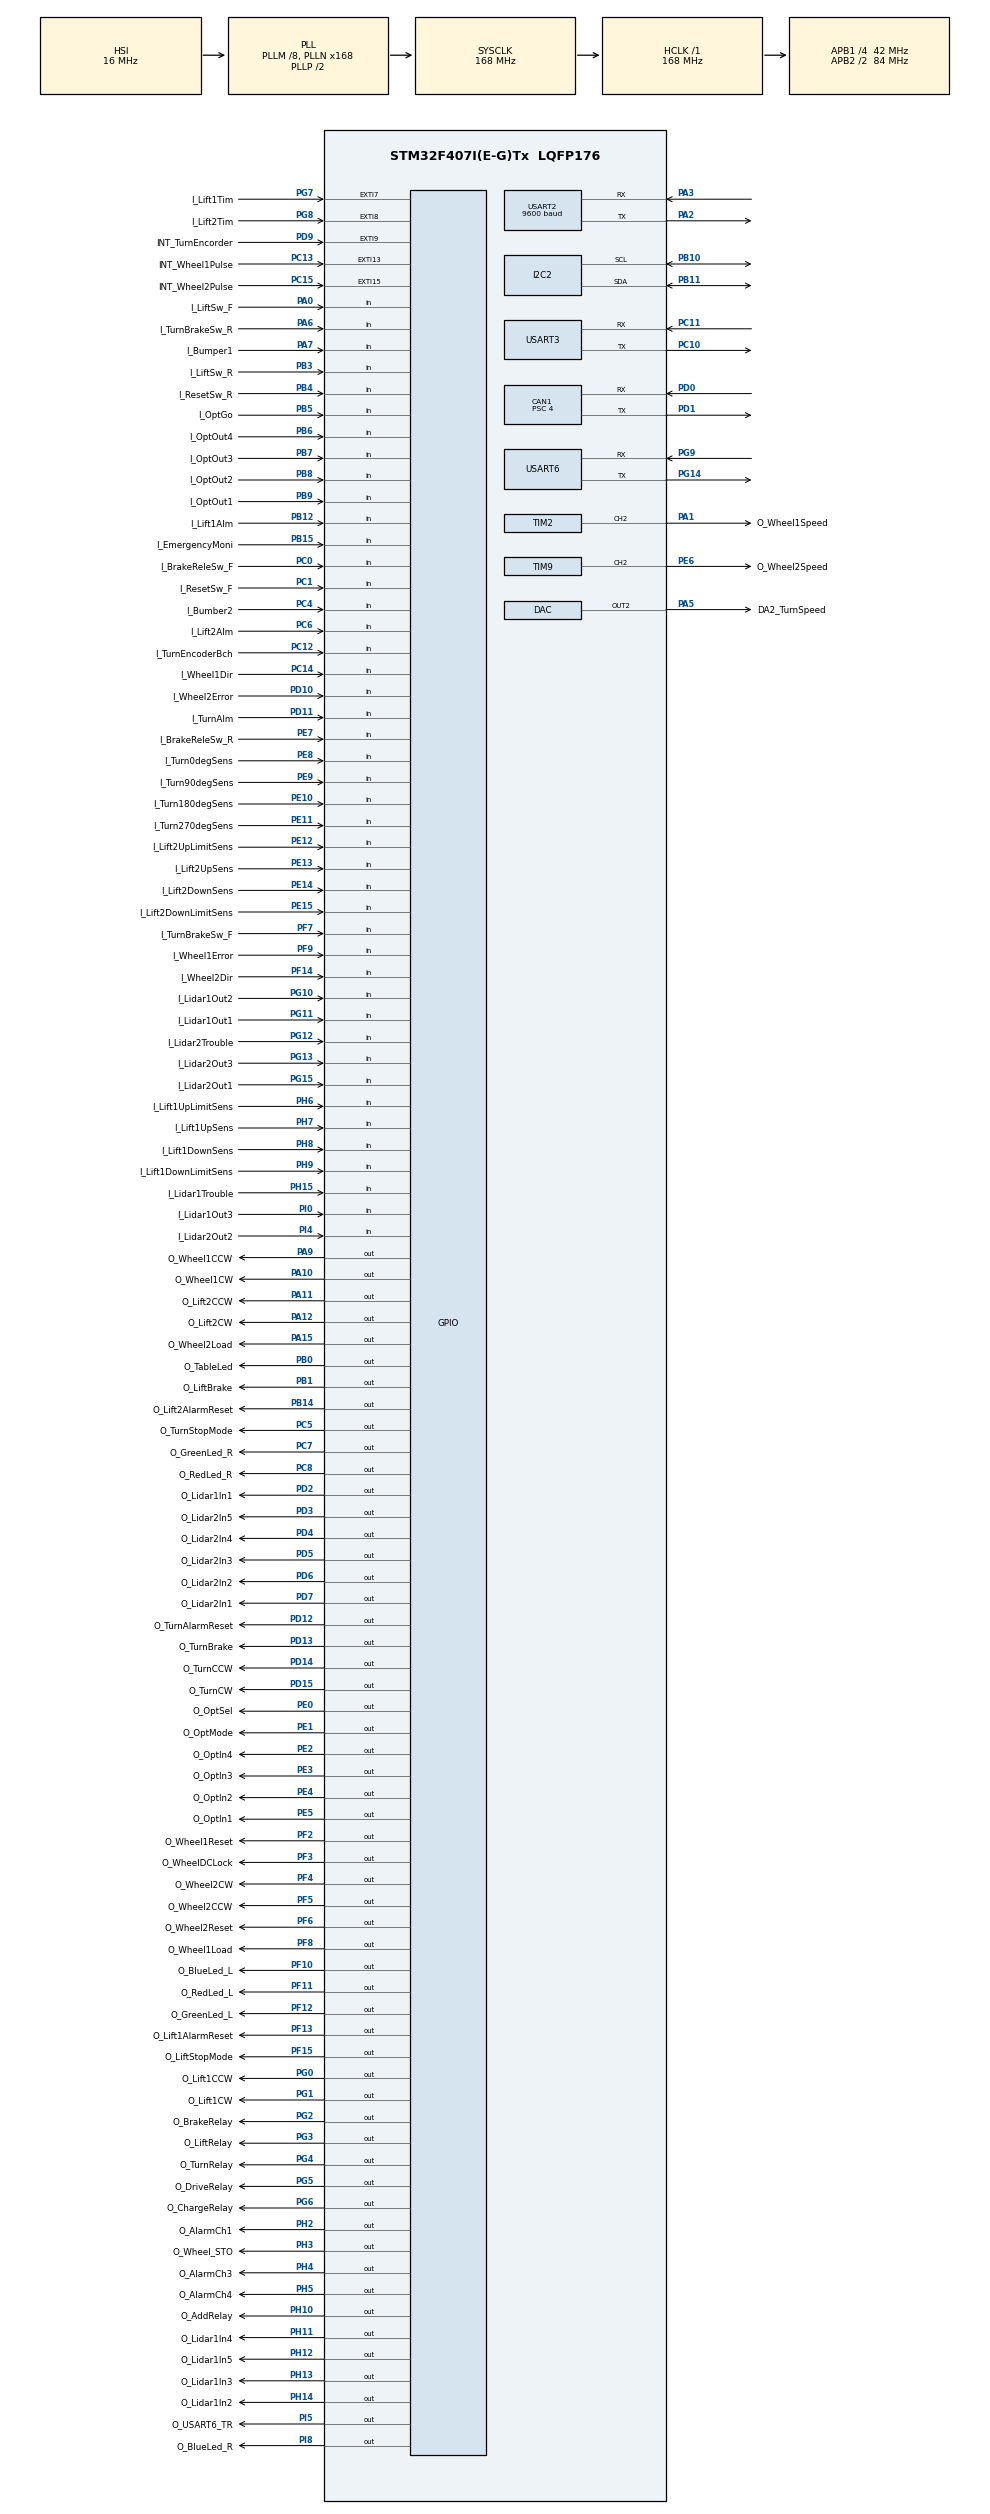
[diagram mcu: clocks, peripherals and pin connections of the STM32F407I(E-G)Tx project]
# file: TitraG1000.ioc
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CAN1.BS1=CAN_BS1_15TQ
CAN1.BS2=CAN_BS2_5TQ
CAN1.CalculateTimeQuantum=95.23809523809524
CAN1.Prescaler=4
Dma.Request0=USART2_RX
Dma.Request1=USART2_TX
Dma.Request2=USART3_TX
Dma.Request3=USART3_RX
Dma.Request4=USART6_TX
Dma.USART2_RX.0.Direction=DMA_PERIPH_TO_MEMORY
Dma.USART2_RX.0.FIFOMode=DMA_FIFOMODE_DISABLE
Dma.USART2_RX.0.Instance=DMA1_Stream5
Dma.USART2_RX.0.MemDataAlignment=DMA_MDATAALIGN_BYTE
Dma.USART2_RX.0.MemInc=DMA_MINC_ENABLE
Dma.USART2_RX.0.Mode=DMA_CIRCULAR
Dma.USART2_RX.0.PeriphDataAlignment=DMA_PDATAALIGN_BYTE
Dma.USART2_RX.0.PeriphInc=DMA_PINC_DISABLE
Dma.USART2_RX.0.Priority=DMA_PRIORITY_MEDIUM
Dma.USART2_TX.1.Direction=DMA_MEMORY_TO_PERIPH
Dma.USART2_TX.1.FIFOMode=DMA_FIFOMODE_DISABLE
Dma.USART2_TX.1.Instance=DMA1_Stream6
Dma.USART2_TX.1.MemDataAlignment=DMA_MDATAALIGN_BYTE
Dma.USART2_TX.1.MemInc=DMA_MINC_ENABLE
Dma.USART2_TX.1.Mode=DMA_NORMAL
Dma.USART2_TX.1.PeriphDataAlignment=DMA_PDATAALIGN_BYTE
Dma.USART2_TX.1.PeriphInc=DMA_PINC_DISABLE
Dma.USART2_TX.1.Priority=DMA_PRIORITY_MEDIUM
Dma.USART3_RX.3.Direction=DMA_PERIPH_TO_MEMORY
Dma.USART3_RX.3.FIFOMode=DMA_FIFOMODE_DISABLE
Dma.USART3_RX.3.Instance=DMA1_Stream1
Dma.USART3_RX.3.MemDataAlignment=DMA_MDATAALIGN_BYTE
Dma.USART3_RX.3.MemInc=DMA_MINC_ENABLE
Dma.USART3_RX.3.Mode=DMA_CIRCULAR
Dma.USART3_RX.3.PeriphDataAlignment=DMA_PDATAALIGN_BYTE
Dma.USART3_RX.3.PeriphInc=DMA_PINC_DISABLE
Dma.USART3_RX.3.Priority=DMA_PRIORITY_HIGH
Dma.USART3_TX.2.Direction=DMA_MEMORY_TO_PERIPH
Dma.USART3_TX.2.FIFOMode=DMA_FIFOMODE_DISABLE
Dma.USART3_TX.2.Instance=DMA1_Stream3
Dma.USART3_TX.2.MemDataAlignment=DMA_MDATAALIGN_BYTE
Dma.USART3_TX.2.MemInc=DMA_MINC_ENABLE
Dma.USART3_TX.2.Mode=DMA_NORMAL
Dma.USART3_TX.2.PeriphDataAlignment=DMA_PDATAALIGN_BYTE
Dma.USART3_TX.2.PeriphInc=DMA_PINC_DISABLE
Dma.USART3_TX.2.Priority=DMA_PRIORITY_HIGH
Dma.USART6_TX.4.Direction=DMA_MEMORY_TO_PERIPH
Dma.USART6_TX.4.FIFOMode=DMA_FIFOMODE_DISABLE
Dma.USART6_TX.4.Instance=DMA2_Stream6
Dma.USART6_TX.4.MemDataAlignment=DMA_MDATAALIGN_BYTE
Dma.USART6_TX.4.MemInc=DMA_MINC_ENABLE
Dma.USART6_TX.4.Mode=DMA_NORMAL
Dma.USART6_TX.4.PeriphDataAlignment=DMA_PDATAALIGN_BYTE
Dma.USART6_TX.4.PeriphInc=DMA_PINC_DISABLE
Dma.USART6_TX.4.Priority=DMA_PRIORITY_LOW
Mcu.Family=STM32F4
Mcu.Name=STM32F407I(E-G)Tx
Mcu.Package=LQFP176
NVIC.CAN1_RX0_IRQn=true\:0\:0\:false\:false\:true\:true\:true
NVIC.DMA1_Stream1_IRQn=true\:0\:0\:false\:false\:true\:false\:true
NVIC.DMA1_Stream3_IRQn=true\:0\:0\:false\:false\:true\:false\:true
NVIC.DMA1_Stream5_IRQn=true\:0\:0\:false\:false\:true\:false\:true
NVIC.DMA1_Stream6_IRQn=true\:0\:0\:false\:false\:true\:false\:true
NVIC.DMA2_Stream6_IRQn=true\:0\:0\:false\:false\:true\:false\:true
NVIC.EXTI15_10_IRQn=true\:0\:0\:false\:false\:true\:true\:true
NVIC.EXTI9_5_IRQn=true\:0\:0\:false\:false\:true\:true\:true
NVIC.PriorityGroup=NVIC_PRIORITYGROUP_4
NVIC.TIM4_IRQn=true\:0\:0\:false\:false\:true\:true\:true
NVIC.USART2_IRQn=true\:0\:0\:false\:false\:true\:true\:true
NVIC.USART3_IRQn=true\:0\:0\:false\:false\:true\:true\:true
NVIC.USART6_IRQn=true\:0\:0\:false\:false\:true\:true\:true
PA0-WKUP.GPIO_Label=I_LiftSw_F
PA0-WKUP.Signal=GPIO_Input
PA1.GPIO_Label=O_Wheel1Speed
PA1.Signal=S_TIM2_CH2
PA10.GPIO_Label=O_Wheel1CW
PA10.Signal=GPIO_Output
PA11.GPIO_Label=O_Lift2CCW
PA11.GPIO_PuPd=GPIO_PULLUP
PA11.Signal=GPIO_Output
PA12.GPIO_Label=O_Lift2CW
PA12.GPIO_PuPd=GPIO_PULLUP
PA12.Signal=GPIO_Output
PA15.GPIO_Label=O_Wheel2Load
PA15.Signal=GPIO_Output
PA2.Mode=IrDA
PA2.Signal=USART2_TX
PA3.Mode=IrDA
PA3.Signal=USART2_RX
PA5.GPIO_Label=DA2_TurnSpeed
PA5.Signal=COMP_DAC2_group
PA6.GPIO_Label=I_TurnBrakeSw_R
PA6.Signal=GPIO_Input
PA7.GPIO_Label=I_Bumper1
PA7.Signal=GPIO_Input
PA9.GPIO_Label=O_Wheel1CCW
PA9.Signal=GPIO_Output
PB0.GPIO_Label=O_TableLed
PB0.Signal=GPIO_Output
PB1.GPIO_Label=O_LiftBrake
PB1.GPIO_PuPd=GPIO_PULLUP
PB1.Signal=GPIO_Output
PB10.Mode=I2C
PB10.Signal=I2C2_SCL
PB11.Mode=I2C
PB11.Signal=I2C2_SDA
PB12.GPIO_Label=I_Lift1Alm
PB12.Signal=GPIO_Input
PB14.GPIO_Label=O_Lift2AlarmReset
PB14.GPIO_PuPd=GPIO_PULLUP
PB14.Signal=GPIO_Output
PB15.GPIO_Label=I_EmergencyMoni
PB15.Signal=GPIO_Input
PB3.GPIO_Label=I_LiftSw_R
PB3.Signal=GPIO_Input
PB4.GPIO_Label=I_ResetSw_R
PB4.Signal=GPIO_Input
PB5.GPIO_Label=I_OptGo
PB5.Signal=GPIO_Input
PB6.GPIO_Label=I_OptOut4
PB6.Signal=GPIO_Input
PB7.GPIO_Label=I_OptOut3
PB7.Signal=GPIO_Input
PB8.GPIO_Label=I_OptOut2
PB8.Signal=GPIO_Input
PB9.GPIO_Label=I_OptOut1
PB9.Signal=GPIO_Input
PC0.GPIO_Label=I_BrakeReleSw_F
PC0.Signal=GPIO_Input
PC1.GPIO_Label=I_ResetSw_F
PC1.Signal=GPIO_Input
PC10.Mode=Asynchronous
PC10.Signal=USART3_TX
PC11.Mode=Asynchronous
PC11.Signal=USART3_RX
PC12.GPIO_Label=I_TurnEncoderBch
PC12.Signal=GPIO_Input
PC13-ANTI_TAMP.GPIO_Label=INT_Wheel1Pulse
PC13-ANTI_TAMP.Signal=GPXTI13
PC14-OSC32_IN.GPIO_Label=I_Wheel1Dir
PC14-OSC32_IN.Signal=GPIO_Input
PC15-OSC32_OUT.GPIO_Label=INT_Wheel2Pulse
PC15-OSC32_OUT.Signal=GPXTI15
PC4.GPIO_Label=I_Bumber2
PC4.Signal=GPIO_Input
PC5.GPIO_Label=O_TurnStopMode
PC5.GPIO_PuPd=GPIO_PULLUP
PC5.Signal=GPIO_Output
PC6.GPIO_Label=I_Lift2Alm
PC6.Signal=GPIO_Input
PC7.GPIO_Label=O_GreenLed_R
PC7.Signal=GPIO_Output
PC8.GPIO_Label=O_RedLed_R
PC8.Signal=GPIO_Output
PD0.Mode=Master
PD0.Signal=CAN1_RX
PD1.Mode=Master
PD1.Signal=CAN1_TX
PD10.GPIO_Label=I_Wheel2Error
PD10.Signal=GPIO_Input
PD11.GPIO_Label=I_TurnAlm
PD11.Signal=GPIO_Input
PD12.GPIO_Label=O_TurnAlarmReset
PD12.GPIO_PuPd=GPIO_PULLUP
PD12.Signal=GPIO_Output
PD13.GPIO_Label=O_TurnBrake
PD13.GPIO_PuPd=GPIO_PULLUP
PD13.Signal=GPIO_Output
PD14.GPIO_Label=O_TurnCCW
PD14.GPIO_PuPd=GPIO_PULLUP
PD14.Signal=GPIO_Output
PD15.GPIO_Label=O_TurnCW
PD15.GPIO_PuPd=GPIO_PULLUP
PD15.Signal=GPIO_Output
PD2.GPIO_Label=O_Lidar1In1
PD2.Signal=GPIO_Output
PD3.GPIO_Label=O_Lidar2In5
PD3.Signal=GPIO_Output
PD4.GPIO_Label=O_Lidar2In4
PD4.Signal=GPIO_Output
PD5.GPIO_Label=O_Lidar2In3
PD5.Signal=GPIO_Output
PD6.GPIO_Label=O_Lidar2In2
PD6.Signal=GPIO_Output
PD7.GPIO_Label=O_Lidar2In1
PD7.Signal=GPIO_Output
PD9.GPIO_Label=INT_TurnEncorder
PD9.Signal=GPXTI9
PE0.GPIO_Label=O_OptSel
PE0.Signal=GPIO_Output
PE1.GPIO_Label=O_OptMode
PE1.Signal=GPIO_Output
PE10.GPIO_Label=I_Turn180degSens
PE10.GPIO_PuPd=GPIO_PULLUP
PE10.Signal=GPIO_Input
PE11.GPIO_Label=I_Turn270degSens
PE11.GPIO_PuPd=GPIO_PULLUP
PE11.Signal=GPIO_Input
PE12.GPIO_Label=I_Lift2UpLimitSens
PE12.GPIO_PuPd=GPIO_PULLUP
PE12.Signal=GPIO_Input
PE13.GPIO_Label=I_Lift2UpSens
PE13.GPIO_PuPd=GPIO_PULLUP
PE13.Signal=GPIO_Input
PE14.GPIO_Label=I_Lift2DownSens
PE14.GPIO_PuPd=GPIO_PULLUP
PE14.Signal=GPIO_Input
PE15.GPIO_Label=I_Lift2DownLimitSens
PE15.GPIO_PuPd=GPIO_PULLUP
PE15.Signal=GPIO_Input
PE2.GPIO_Label=O_OptIn4
PE2.Signal=GPIO_Output
PE3.GPIO_Label=O_OptIn3
PE3.Signal=GPIO_Output
PE4.GPIO_Label=O_OptIn2
PE4.Signal=GPIO_Output
PE5.GPIO_Label=O_OptIn1
PE5.Signal=GPIO_Output
PE6.GPIO_Label=O_Wheel2Speed
PE6.Signal=S_TIM9_CH2
PE7.GPIO_Label=I_BrakeReleSw_R
PE7.Signal=GPIO_Input
PE8.GPIO_Label=I_Turn0degSens
PE8.GPIO_PuPd=GPIO_PULLUP
PE8.Signal=GPIO_Input
PE9.GPIO_Label=I_Turn90degSens
PE9.GPIO_PuPd=GPIO_PULLUP
PE9.Signal=GPIO_Input
PF10.GPIO_Label=O_BlueLed_L
PF10.Signal=GPIO_Output
PF11.GPIO_Label=O_RedLed_L
PF11.Signal=GPIO_Output
PF12.GPIO_Label=O_GreenLed_L
PF12.Signal=GPIO_Output
PF13.GPIO_Label=O_Lift1AlarmReset
PF13.GPIO_PuPd=GPIO_PULLUP
PF13.Signal=GPIO_Output
PF14.GPIO_Label=I_Wheel2Dir
PF14.Signal=GPIO_Input
PF15.GPIO_Label=O_LiftStopMode
PF15.GPIO_PuPd=GPIO_PULLUP
PF15.Signal=GPIO_Output
PF2.GPIO_Label=O_Wheel1Reset
PF2.Signal=GPIO_Output
PF3.GPIO_Label=O_WheelDCLock
PF3.Signal=GPIO_Output
PF4.GPIO_Label=O_Wheel2CW
PF4.Signal=GPIO_Output
PF5.GPIO_Label=O_Wheel2CCW
PF5.Signal=GPIO_Output
PF6.GPIO_Label=O_Wheel2Reset
PF6.Signal=GPIO_Output
PF7.GPIO_Label=I_TurnBrakeSw_F
PF7.Signal=GPIO_Input
PF8.GPIO_Label=O_Wheel1Load
PF8.Signal=GPIO_Output
PF9.GPIO_Label=I_Wheel1Error
PF9.Signal=GPIO_Input
PG0.GPIO_Label=O_Lift1CCW
PG0.GPIO_PuPd=GPIO_PULLUP
PG0.Signal=GPIO_Output
PG1.GPIO_Label=O_Lift1CW
PG1.GPIO_PuPd=GPIO_PULLUP
PG1.Signal=GPIO_Output
PG10.GPIO_Label=I_Lidar1Out2
PG10.Signal=GPIO_Input
PG11.GPIO_Label=I_Lidar1Out1
PG11.Signal=GPIO_Input
PG12.GPIO_Label=I_Lidar2Trouble
PG12.Signal=GPIO_Input
PG13.GPIO_Label=I_Lidar2Out3
PG13.Signal=GPIO_Input
PG14.Mode=Asynchronous
PG14.Signal=USART6_TX
PG15.GPIO_Label=I_Lidar2Out1
PG15.Signal=GPIO_Input
PG2.GPIO_Label=O_BrakeRelay
PG2.Signal=GPIO_Output
PG3.GPIO_Label=O_LiftRelay
PG3.Signal=GPIO_Output
PG4.GPIO_Label=O_TurnRelay
PG4.Signal=GPIO_Output
PG5.GPIO_Label=O_DriveRelay
PG5.Signal=GPIO_Output
PG6.GPIO_Label=O_ChargeRelay
PG6.Signal=GPIO_Output
PG7.GPIO_Label=I_Lift1Tim
PG7.Signal=GPXTI7
PG8.GPIO_Label=I_Lift2Tim
PG8.Signal=GPXTI8
PG9.Mode=Asynchronous
PG9.Signal=USART6_RX
PH10.GPIO_Label=O_AddRelay
PH10.PinState=GPIO_PIN_SET
PH10.Signal=GPIO_Output
PH11.GPIO_Label=O_Lidar1In4
PH11.Signal=GPIO_Output
PH12.GPIO_Label=O_Lidar1In5
PH12.Signal=GPIO_Output
PH13.GPIO_Label=O_Lidar1In3
PH13.Signal=GPIO_Output
PH14.GPIO_Label=O_Lidar1In2
PH14.Signal=GPIO_Output
PH15.GPIO_Label=I_Lidar1Trouble
PH15.Signal=GPIO_Input
PH2.GPIO_Label=O_AlarmCh1
PH2.Signal=GPIO_Output
PH3.GPIO_Label=O_Wheel_STO
PH3.Signal=GPIO_Output
PH4.GPIO_Label=O_AlarmCh3
PH4.Signal=GPIO_Output
PH5.GPIO_Label=O_AlarmCh4
PH5.Signal=GPIO_Output
PH6.GPIO_Label=I_Lift1UpLimitSens
PH6.GPIO_PuPd=GPIO_PULLUP
PH6.Signal=GPIO_Input
PH7.GPIO_Label=I_Lift1UpSens
PH7.GPIO_PuPd=GPIO_PULLUP
PH7.Signal=GPIO_Input
PH8.GPIO_Label=I_Lift1DownSens
PH8.GPIO_PuPd=GPIO_PULLUP
PH8.Signal=GPIO_Input
PH9.GPIO_Label=I_Lift1DownLimitSens
PH9.GPIO_PuPd=GPIO_PULLUP
PH9.Signal=GPIO_Input
PI0.GPIO_Label=I_Lidar1Out3
PI0.Signal=GPIO_Input
PI4.GPIO_Label=I_Lidar2Out2
PI4.Signal=GPIO_Input
PI5.GPIO_Label=O_USART6_TR
PI5.Signal=GPIO_Output
PI8-\ ANTI\ TAMP2.GPIO_Label=O_BlueLed_R
PI8-\ ANTI\ TAMP2.Signal=GPIO_Output
ProjectManager.HeapSize=0x200
ProjectManager.StackSize=0x400
ProjectManager.TargetToolchain=SW4STM32
RCC.48MHZClocksFreq_Value=84000000
RCC.AHBFreq_Value=168000000
RCC.APB1CLKDivider=RCC_HCLK_DIV4
RCC.APB1Freq_Value=42000000
RCC.APB1TimFreq_Value=84000000
RCC.APB2CLKDivider=RCC_HCLK_DIV2
RCC.APB2Freq_Value=84000000
RCC.APB2TimFreq_Value=168000000
RCC.CortexFreq_Value=168000000
RCC.HCLKFreq_Value=168000000
RCC.HSE_VALUE=25000000
RCC.HSI_VALUE=16000000
RCC.LSE_VALUE=32768
RCC.PLLM=8
RCC.PLLN=168
RCC.SYSCLKFreq_VALUE=168000000
RCC.SYSCLKSource=RCC_SYSCLKSOURCE_PLLCLK
RCC.VCOOutputFreq_Value=336000000
SH.COMP_DAC2_group.0=DAC_OUT2,DAC_OUT2
SH.S_TIM2_CH2.0=TIM2_CH2,Output Compare2 CH2
SH.S_TIM9_CH2.0=TIM9_CH2,Output Compare2 CH2
TIM1.AutoReloadPreload=TIM_AUTORELOAD_PRELOAD_ENABLE
TIM1.Prescaler=168-1
TIM2.AutoReloadPreload=TIM_AUTORELOAD_PRELOAD_ENABLE
TIM2.Channel-Output\ Compare2\ CH2=TIM_CHANNEL_2
TIM2.OCMode_2=TIM_OCMODE_TOGGLE
TIM2.Prescaler=84-1
TIM4.AutoReloadPreload=TIM_AUTORELOAD_PRELOAD_ENABLE
TIM4.Prescaler=32
TIM5.Period=4294967295
TIM5.Prescaler=100-1
TIM6.Period=65535
TIM6.Prescaler=2000-1
TIM7.Period=65535
TIM7.Prescaler=2000-1
TIM9.AutoReloadPreload=TIM_AUTORELOAD_PRELOAD_ENABLE
TIM9.Channel-Output\ Compare2\ CH2=TIM_CHANNEL_2
TIM9.OCMode_2=TIM_OCMODE_TOGGLE
TIM9.Prescaler=168-1
USART2.BaudRate=9600
USART2.VirtualMode=VM_IRDA
USART3.VirtualMode=VM_ASYNC
USART6.Parity=PARITY_EVEN
USART6.VirtualMode=VM_ASYNC
USART6.WordLength=WORDLENGTH_9B
VP_TIM1_VS_ClockSourceINT.Mode=Internal
VP_TIM2_VS_ClockSourceINT.Mode=Internal
VP_TIM4_VS_ClockSourceINT.Mode=Internal
VP_TIM5_VS_ClockSourceINT.Mode=Internal
VP_TIM6_VS_ClockSourceINT.Mode=Enable_Timer
VP_TIM7_VS_ClockSourceINT.Mode=Enable_Timer
VP_TIM9_VS_ClockSourceINT.Mode=Internal
board=custom

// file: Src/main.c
/* USER CODE BEGIN Header */
/**
  ******************************************************************************
  * @file           : main.c
  * @brief          : Main program body
  ******************************************************************************
  * @attention
  *
  * <h2><center>&copy; Copyright (c) 2021 STMicroelectronics.
  * All rights reserved.</center></h2>
  *
  * This software component is licensed by ST under BSD 3-Clause license,
  * the "License"; You may not use this file except in compliance with the
  * License. You may obtain a copy of the License at:
  *                        opensource.org/licenses/BSD-3-Clause
  *
  ******************************************************************************
  */
/* USER CODE END Header */

#include "main.h"

/* USER CODE BEGIN Includes */
#include "conf.h"
#include "tbt.h"
#include "lift.h"
#include "turn.h"
#include "nuc.h"
#include "Cntrl_Proc.h"
#include "battery.h"
#include "charge.h"
#include "wheel.h"
#include "task_charger_link.h"
#include "sound.h"
#include "lidar.h"
#include "syncturn.h"
#include "led.h"
#include "wheel_test.h"
#include "load.h"
#include "can.h"

/* USER CODE END Includes */

CAN_HandleTypeDef hcan1;

DAC_HandleTypeDef hdac;

I2C_HandleTypeDef hi2c2;

TIM_HandleTypeDef htim1;
TIM_HandleTypeDef htim2;
TIM_HandleTypeDef htim4;
TIM_HandleTypeDef htim5;
TIM_HandleTypeDef htim6;
TIM_HandleTypeDef htim7;
TIM_HandleTypeDef htim9;

IRDA_HandleTypeDef hirda2;
UART_HandleTypeDef huart3;
UART_HandleTypeDef huart6;
DMA_HandleTypeDef hdma_usart2_rx;
DMA_HandleTypeDef hdma_usart2_tx;
DMA_HandleTypeDef hdma_usart3_tx;
DMA_HandleTypeDef hdma_usart3_rx;
DMA_HandleTypeDef hdma_usart6_tx;

/* USER CODE BEGIN PV */
static uint32_t tim5_cnt = 0;
static uint16_t	tim6_cnt = 0;
static uint16_t	tim7_cnt = 0;
static uint16_t	r_wheel_enc = 0;
static uint16_t	l_wheel_enc = 0;
static uint16_t turn_encoder = 0;
const uint8_t f_version[ver_length] = {DEST_HIGH,DEST_LOW, MAJOR_HIGH,MAJOR_LOW, MINOR_HIGH,MINOR_LOW, BATCH_HIGH,BATCH_LOW};
/* USER CODE END PV */

void SystemClock_Config(void);
static void MX_GPIO_Init(void);
static void MX_DMA_Init(void);
static void MX_DAC_Init(void);
static void MX_TIM2_Init(void);
static void MX_TIM9_Init(void);
static void MX_USART2_IRDA_Init(void);
static void MX_I2C2_Init(void);
static void MX_CAN1_Init(void);
static void MX_USART3_UART_Init(void);
static void MX_USART6_UART_Init(void);
static void MX_TIM1_Init(void);
static void MX_TIM4_Init(void);
static void MX_TIM5_Init(void);
static void MX_TIM6_Init(void);
static void MX_TIM7_Init(void);
/* USER CODE BEGIN PFP */
void enc_pulse_tim_start(void);
/* USER CODE END PFP */

/* USER CODE BEGIN 0 */

uint8_t get_fw_version(uint8_t num) {

	uint8_t ret = 0;

	if (num < ver_length) {
		ret = f_version[num];
	}
	return ret;
}
/* USER CODE END 0 */

int main(void)
{

  /* MCU Configuration--------------------------------------------------------*/

  /* Reset of all peripherals, Initializes the Flash interface and the Systick. */
  HAL_Init();

  /* Configure the system clock */
  SystemClock_Config();

  /* Initialize all configured peripherals */
  MX_GPIO_Init();
  MX_DMA_Init();
  MX_DAC_Init();
  MX_TIM2_Init();
  MX_TIM9_Init();
  MX_USART2_IRDA_Init();
  MX_I2C2_Init();
  MX_CAN1_Init();
  MX_USART3_UART_Init();
  MX_USART6_UART_Init();
  MX_TIM1_Init();
  MX_TIM4_Init();
  MX_TIM5_Init();
  MX_TIM6_Init();
  MX_TIM7_Init();
  /* USER CODE BEGIN 2 */
  nuc_init();
  chagerlink_init();
  HAL_DAC_Start(&hdac, DAC_CHANNEL_2);

  load_init();
  turn_init();
  charge_proc_init();
  lift_init();
  init_timer();											// initiate timer
  read_HardwareID();									// read microcomputer board ID
  init_lidar_wait_time();
  enc_pulse_tim_start();
  battery_init();
  can_filter_setting();
  HAL_CAN_Start(&hcan1);
  HAL_CAN_ActivateNotification(&hcan1, CAN_IT_RX_FIFO0_MSG_PENDING);
#if BATTERY_TYPE == MURATA_BATTERY
  CAN_filter_setting();
  HAL_CAN_Start(&hcan1);
  HAL_CAN_ActivateNotification(&hcan1, CAN_IT_RX_FIFO0_MSG_PENDING);
#endif
  /* USER CODE END 2 */

  /* Infinite loop */
  /* USER CODE BEGIN WHILE */
  while (1)
  {

	  if (check_timer(CNT_GO4) == TIME_UP)
	  {
		  battery_monitor();
		  set_utimer(CNT_GO4, CNT_PERIOD4);				// 20sec
	  }

	  if (check_timer(CNT_GO3) == TIME_UP)
	  {
		  transmit_charge_cmd();
		  set_utimer(CNT_GO3, CNT_PERIOD3);				// 300msec
	  }

	  if (check_timer(CNT_GO2) == TIME_UP)
	  {
		  ck_com_error();
		  sound_cntrol();
		  cmnd_proc();
		  set_utimer(CNT_GO2, CNT_PERIOD2);				// 100msec
	  }

	  if (check_timer(CNT_GO1) == TIME_UP)
	  {
		  scan_proc1();
		  load_measure();
		  set_utimer(CNT_GO1, CNT_PERIOD1);				// 20msec
	  }

	  if (check_timer(CNT_WHEEL_ENCODER) == TIME_UP) {	// エンコーダー取得のための関数
		  set_utimer(CNT_WHEEL_ENCODER, CNT_PROCPERIOD);
	  }

	  if (check_timer(CNT_PROCESS) == TIME_UP)
	  {
		  if (!Is_SyncTurnning()) {
			  lift_cntrl();
			  charge_proc();	// Charge Sequence
			  wheel_log_update();
		  }
		  led_proc();
		  set_utimer(CNT_PROCESS, CNT_PROCPERIOD);		// 10msec
	  }

	  if (check_timer(CNT_GO7) == TIME_UP)
	  {
		  check_nuc_receive_data();
		  int16_t left_speed = get_LeftWheel_Speed();
		  int16_t right_speed = get_RightWheel_Speed();
		  wheel_cntrl(left_speed, right_speed);
		  //ck_motor_receive_data();
		  set_utimer(CNT_GO7, CNT_1MSEC);				// 1msec
	  }

	  if (get_i2c2_init() != 0) {
		  MX_I2C2_Init();
		  reset_i2c2_init();
	  }

	  if (check_timer(CNT_TURN) == TIME_UP)
	  {
		  if (Is_SyncTurnning() == 0) {
			  turn_cntrl();
		  }
		  set_utimer(CNT_TURN, CNT_TURNPERIOD);		// 1msec
	  }

	  if (check_timer(CNT_SYNCTURN) == TIME_UP) {
		  syncturn_ctrl();
		  set_utimer(CNT_SYNCTURN, CNT_SYNCTURN_VAL);
	  }

	  // log output(for development)
	  if((get_sync_dump_req() == 1) && (get_sync_dump_comp() != 1)){
		  syncturn_log_dump();
	  }
	  else if((get_turn_dump_req() == 1) && (get_turn_dump_comp() != 1)){
		  turn_log_dump();
	  }
	  else if((get_wheel_dump_req() == 1) && (get_wheel_dump_comp() != 1)){
		  wheel_log_dump();
	  }
	  else if((get_wheel_test_dump_req() == 1) && (get_wheel_test_dump_comp() != 1)){
		  wheel_test_log_dump();
	  }
  }
    /* USER CODE END WHILE */

}

void SystemClock_Config(void)
{
  RCC_OscInitTypeDef RCC_OscInitStruct = {0};
  RCC_ClkInitTypeDef RCC_ClkInitStruct = {0};

  /** Configure the main internal regulator output voltage
  */
  __HAL_RCC_PWR_CLK_ENABLE();
  __HAL_PWR_VOLTAGESCALING_CONFIG(PWR_REGULATOR_VOLTAGE_SCALE1);
  /** Initializes the CPU, AHB and APB busses clocks
  */
  RCC_OscInitStruct.OscillatorType = RCC_OSCILLATORTYPE_HSI;
  RCC_OscInitStruct.HSIState = RCC_HSI_ON;
  RCC_OscInitStruct.HSICalibrationValue = RCC_HSICALIBRATION_DEFAULT;
  RCC_OscInitStruct.PLL.PLLState = RCC_PLL_ON;
  RCC_OscInitStruct.PLL.PLLSource = RCC_PLLSOURCE_HSI;
  RCC_OscInitStruct.PLL.PLLM = 8;
  RCC_OscInitStruct.PLL.PLLN = 168;
  RCC_OscInitStruct.PLL.PLLP = RCC_PLLP_DIV2;
  RCC_OscInitStruct.PLL.PLLQ = 4;
  if (HAL_RCC_OscConfig(&RCC_OscInitStruct) != HAL_OK)
  {
    Error_Handler();
  }
  /** Initializes the CPU, AHB and APB busses clocks
  */
  RCC_ClkInitStruct.ClockType = RCC_CLOCKTYPE_HCLK|RCC_CLOCKTYPE_SYSCLK
                              |RCC_CLOCKTYPE_PCLK1|RCC_CLOCKTYPE_PCLK2;
  RCC_ClkInitStruct.SYSCLKSource = RCC_SYSCLKSOURCE_PLLCLK;
  RCC_ClkInitStruct.AHBCLKDivider = RCC_SYSCLK_DIV1;
  RCC_ClkInitStruct.APB1CLKDivider = RCC_HCLK_DIV4;
  RCC_ClkInitStruct.APB2CLKDivider = RCC_HCLK_DIV2;

  if (HAL_RCC_ClockConfig(&RCC_ClkInitStruct, FLASH_LATENCY_5) != HAL_OK)
  {
    Error_Handler();
  }
}

static void MX_CAN1_Init(void)
{

  hcan1.Instance = CAN1;
  hcan1.Init.Prescaler = 4;
  hcan1.Init.Mode = CAN_MODE_NORMAL;
  hcan1.Init.SyncJumpWidth = CAN_SJW_1TQ;
  hcan1.Init.TimeSeg1 = CAN_BS1_15TQ;
  hcan1.Init.TimeSeg2 = CAN_BS2_5TQ;
  hcan1.Init.TimeTriggeredMode = DISABLE;
  hcan1.Init.AutoBusOff = DISABLE;
  hcan1.Init.AutoWakeUp = DISABLE;
  hcan1.Init.AutoRetransmission = DISABLE;
  hcan1.Init.ReceiveFifoLocked = DISABLE;
  hcan1.Init.TransmitFifoPriority = DISABLE;
  if (HAL_CAN_Init(&hcan1) != HAL_OK)
  {
    Error_Handler();
  }

}

static void MX_DAC_Init(void)
{

  DAC_ChannelConfTypeDef sConfig = {0};

  /** DAC Initialization
  */
  hdac.Instance = DAC;
  if (HAL_DAC_Init(&hdac) != HAL_OK)
  {
    Error_Handler();
  }
  /** DAC channel OUT2 config
  */
  sConfig.DAC_Trigger = DAC_TRIGGER_NONE;
  sConfig.DAC_OutputBuffer = DAC_OUTPUTBUFFER_ENABLE;
  if (HAL_DAC_ConfigChannel(&hdac, &sConfig, DAC_CHANNEL_2) != HAL_OK)
  {
    Error_Handler();
  }

}

static void MX_I2C2_Init(void)
{

  hi2c2.Instance = I2C2;
  hi2c2.Init.ClockSpeed = 100000;
  hi2c2.Init.DutyCycle = I2C_DUTYCYCLE_2;
  hi2c2.Init.OwnAddress1 = 0;
  hi2c2.Init.AddressingMode = I2C_ADDRESSINGMODE_7BIT;
  hi2c2.Init.DualAddressMode = I2C_DUALADDRESS_DISABLE;
  hi2c2.Init.OwnAddress2 = 0;
  hi2c2.Init.GeneralCallMode = I2C_GENERALCALL_DISABLE;
  hi2c2.Init.NoStretchMode = I2C_NOSTRETCH_DISABLE;
  if (HAL_I2C_Init(&hi2c2) != HAL_OK)
  {
    Error_Handler();
  }

}

static void MX_TIM1_Init(void)
{

  TIM_ClockConfigTypeDef sClockSourceConfig = {0};
  TIM_MasterConfigTypeDef sMasterConfig = {0};

  htim1.Instance = TIM1;
  htim1.Init.Prescaler = 168-1;
  htim1.Init.CounterMode = TIM_COUNTERMODE_UP;
  htim1.Init.Period = 0;
  htim1.Init.ClockDivision = TIM_CLOCKDIVISION_DIV1;
  htim1.Init.RepetitionCounter = 0;
  htim1.Init.AutoReloadPreload = TIM_AUTORELOAD_PRELOAD_ENABLE;
  if (HAL_TIM_Base_Init(&htim1) != HAL_OK)
  {
    Error_Handler();
  }
  sClockSourceConfig.ClockSource = TIM_CLOCKSOURCE_INTERNAL;
  if (HAL_TIM_ConfigClockSource(&htim1, &sClockSourceConfig) != HAL_OK)
  {
    Error_Handler();
  }
  sMasterConfig.MasterOutputTrigger = TIM_TRGO_RESET;
  sMasterConfig.MasterSlaveMode = TIM_MASTERSLAVEMODE_DISABLE;
  if (HAL_TIMEx_MasterConfigSynchronization(&htim1, &sMasterConfig) != HAL_OK)
  {
    Error_Handler();
  }

}

static void MX_TIM2_Init(void)
{

  TIM_ClockConfigTypeDef sClockSourceConfig = {0};
  TIM_MasterConfigTypeDef sMasterConfig = {0};
  TIM_OC_InitTypeDef sConfigOC = {0};

  htim2.Instance = TIM2;
  htim2.Init.Prescaler = 84-1;
  htim2.Init.CounterMode = TIM_COUNTERMODE_UP;
  htim2.Init.Period = 0;
  htim2.Init.ClockDivision = TIM_CLOCKDIVISION_DIV1;
  htim2.Init.AutoReloadPreload = TIM_AUTORELOAD_PRELOAD_ENABLE;
  if (HAL_TIM_Base_Init(&htim2) != HAL_OK)
  {
    Error_Handler();
  }
  sClockSourceConfig.ClockSource = TIM_CLOCKSOURCE_INTERNAL;
  if (HAL_TIM_ConfigClockSource(&htim2, &sClockSourceConfig) != HAL_OK)
  {
    Error_Handler();
  }
  if (HAL_TIM_OC_Init(&htim2) != HAL_OK)
  {
    Error_Handler();
  }
  sMasterConfig.MasterOutputTrigger = TIM_TRGO_RESET;
  sMasterConfig.MasterSlaveMode = TIM_MASTERSLAVEMODE_DISABLE;
  if (HAL_TIMEx_MasterConfigSynchronization(&htim2, &sMasterConfig) != HAL_OK)
  {
    Error_Handler();
  }
  sConfigOC.OCMode = TIM_OCMODE_TOGGLE;
  sConfigOC.Pulse = 0;
  sConfigOC.OCPolarity = TIM_OCPOLARITY_HIGH;
  sConfigOC.OCFastMode = TIM_OCFAST_DISABLE;
  if (HAL_TIM_OC_ConfigChannel(&htim2, &sConfigOC, TIM_CHANNEL_2) != HAL_OK)
  {
    Error_Handler();
  }
  HAL_TIM_MspPostInit(&htim2);

}

static void MX_TIM4_Init(void)
{

  TIM_ClockConfigTypeDef sClockSourceConfig = {0};
  TIM_MasterConfigTypeDef sMasterConfig = {0};

  htim4.Instance = TIM4;
  htim4.Init.Prescaler = 32;
  htim4.Init.CounterMode = TIM_COUNTERMODE_UP;
  htim4.Init.Period = 0;
  htim4.Init.ClockDivision = TIM_CLOCKDIVISION_DIV1;
  htim4.Init.AutoReloadPreload = TIM_AUTORELOAD_PRELOAD_ENABLE;
  if (HAL_TIM_Base_Init(&htim4) != HAL_OK)
  {
    Error_Handler();
  }
  sClockSourceConfig.ClockSource = TIM_CLOCKSOURCE_INTERNAL;
  if (HAL_TIM_ConfigClockSource(&htim4, &sClockSourceConfig) != HAL_OK)
  {
    Error_Handler();
  }
  sMasterConfig.MasterOutputTrigger = TIM_TRGO_RESET;
  sMasterConfig.MasterSlaveMode = TIM_MASTERSLAVEMODE_DISABLE;
  if (HAL_TIMEx_MasterConfigSynchronization(&htim4, &sMasterConfig) != HAL_OK)
  {
    Error_Handler();
  }

}

static void MX_TIM5_Init(void)
{

  TIM_ClockConfigTypeDef sClockSourceConfig = {0};
  TIM_MasterConfigTypeDef sMasterConfig = {0};

  htim5.Instance = TIM5;
  htim5.Init.Prescaler = 100-1;
  htim5.Init.CounterMode = TIM_COUNTERMODE_UP;
  htim5.Init.Period = 4294967295;
  htim5.Init.ClockDivision = TIM_CLOCKDIVISION_DIV1;
  htim5.Init.AutoReloadPreload = TIM_AUTORELOAD_PRELOAD_DISABLE;
  if (HAL_TIM_Base_Init(&htim5) != HAL_OK)
  {
    Error_Handler();
  }
  sClockSourceConfig.ClockSource = TIM_CLOCKSOURCE_INTERNAL;
  if (HAL_TIM_ConfigClockSource(&htim5, &sClockSourceConfig) != HAL_OK)
  {
    Error_Handler();
  }
  sMasterConfig.MasterOutputTrigger = TIM_TRGO_RESET;
  sMasterConfig.MasterSlaveMode = TIM_MASTERSLAVEMODE_DISABLE;
  if (HAL_TIMEx_MasterConfigSynchronization(&htim5, &sMasterConfig) != HAL_OK)
  {
    Error_Handler();
  }

}

static void MX_TIM6_Init(void)
{

  TIM_MasterConfigTypeDef sMasterConfig = {0};

  htim6.Instance = TIM6;
  htim6.Init.Prescaler = 2000-1;
  htim6.Init.CounterMode = TIM_COUNTERMODE_UP;
  htim6.Init.Period = 65535;
  htim6.Init.AutoReloadPreload = TIM_AUTORELOAD_PRELOAD_DISABLE;
  if (HAL_TIM_Base_Init(&htim6) != HAL_OK)
  {
    Error_Handler();
  }
  sMasterConfig.MasterOutputTrigger = TIM_TRGO_RESET;
  sMasterConfig.MasterSlaveMode = TIM_MASTERSLAVEMODE_DISABLE;
  if (HAL_TIMEx_MasterConfigSynchronization(&htim6, &sMasterConfig) != HAL_OK)
  {
    Error_Handler();
  }

}

static void MX_TIM7_Init(void)
{

  TIM_MasterConfigTypeDef sMasterConfig = {0};

  htim7.Instance = TIM7;
  htim7.Init.Prescaler = 2000-1;
  htim7.Init.CounterMode = TIM_COUNTERMODE_UP;
  htim7.Init.Period = 65535;
  htim7.Init.AutoReloadPreload = TIM_AUTORELOAD_PRELOAD_DISABLE;
  if (HAL_TIM_Base_Init(&htim7) != HAL_OK)
  {
    Error_Handler();
  }
  sMasterConfig.MasterOutputTrigger = TIM_TRGO_RESET;
  sMasterConfig.MasterSlaveMode = TIM_MASTERSLAVEMODE_DISABLE;
  if (HAL_TIMEx_MasterConfigSynchronization(&htim7, &sMasterConfig) != HAL_OK)
  {
    Error_Handler();
  }

}

static void MX_TIM9_Init(void)
{

  TIM_ClockConfigTypeDef sClockSourceConfig = {0};
  TIM_OC_InitTypeDef sConfigOC = {0};

  htim9.Instance = TIM9;
  htim9.Init.Prescaler = 168-1;
  htim9.Init.CounterMode = TIM_COUNTERMODE_UP;
  htim9.Init.Period = 0;
  htim9.Init.ClockDivision = TIM_CLOCKDIVISION_DIV1;
  htim9.Init.AutoReloadPreload = TIM_AUTORELOAD_PRELOAD_ENABLE;
  if (HAL_TIM_Base_Init(&htim9) != HAL_OK)
  {
    Error_Handler();
  }
  sClockSourceConfig.ClockSource = TIM_CLOCKSOURCE_INTERNAL;
  if (HAL_TIM_ConfigClockSource(&htim9, &sClockSourceConfig) != HAL_OK)
  {
    Error_Handler();
  }
  if (HAL_TIM_OC_Init(&htim9) != HAL_OK)
  {
    Error_Handler();
  }
  sConfigOC.OCMode = TIM_OCMODE_TOGGLE;
  sConfigOC.Pulse = 0;
  sConfigOC.OCPolarity = TIM_OCPOLARITY_HIGH;
  sConfigOC.OCFastMode = TIM_OCFAST_DISABLE;
  if (HAL_TIM_OC_ConfigChannel(&htim9, &sConfigOC, TIM_CHANNEL_2) != HAL_OK)
  {
    Error_Handler();
  }
  HAL_TIM_MspPostInit(&htim9);

}

static void MX_USART2_IRDA_Init(void)
{

  hirda2.Instance = USART2;
  hirda2.Init.BaudRate = 9600;
  hirda2.Init.WordLength = IRDA_WORDLENGTH_8B;
  hirda2.Init.Parity = IRDA_PARITY_NONE;
  hirda2.Init.Mode = IRDA_MODE_TX_RX;
  hirda2.Init.Prescaler = 1;
  hirda2.Init.IrDAMode = IRDA_POWERMODE_NORMAL;
  if (HAL_IRDA_Init(&hirda2) != HAL_OK)
  {
    Error_Handler();
  }

}

static void MX_USART3_UART_Init(void)
{

  huart3.Instance = USART3;
  huart3.Init.BaudRate = 115200;
  huart3.Init.WordLength = UART_WORDLENGTH_8B;
  huart3.Init.StopBits = UART_STOPBITS_1;
  huart3.Init.Parity = UART_PARITY_NONE;
  huart3.Init.Mode = UART_MODE_TX_RX;
  huart3.Init.HwFlowCtl = UART_HWCONTROL_NONE;
  huart3.Init.OverSampling = UART_OVERSAMPLING_16;
  if (HAL_UART_Init(&huart3) != HAL_OK)
  {
    Error_Handler();
  }

}

static void MX_USART6_UART_Init(void)
{

  huart6.Instance = USART6;
  huart6.Init.BaudRate = 115200;
  huart6.Init.WordLength = UART_WORDLENGTH_9B;
  huart6.Init.StopBits = UART_STOPBITS_1;
  huart6.Init.Parity = UART_PARITY_EVEN;
  huart6.Init.Mode = UART_MODE_TX_RX;
  huart6.Init.HwFlowCtl = UART_HWCONTROL_NONE;
  huart6.Init.OverSampling = UART_OVERSAMPLING_16;
  if (HAL_UART_Init(&huart6) != HAL_OK)
  {
    Error_Handler();
  }

}

static void MX_DMA_Init(void)
{
  /* DMA controller clock enable */
  __HAL_RCC_DMA1_CLK_ENABLE();
  __HAL_RCC_DMA2_CLK_ENABLE();

  /* DMA interrupt init */
  /* DMA1_Stream1_IRQn interrupt configuration */
  HAL_NVIC_SetPriority(DMA1_Stream1_IRQn, 0, 0);
  HAL_NVIC_EnableIRQ(DMA1_Stream1_IRQn);
  /* DMA1_Stream3_IRQn interrupt configuration */
  HAL_NVIC_SetPriority(DMA1_Stream3_IRQn, 0, 0);
  HAL_NVIC_EnableIRQ(DMA1_Stream3_IRQn);
  /* DMA1_Stream5_IRQn interrupt configuration */
  HAL_NVIC_SetPriority(DMA1_Stream5_IRQn, 0, 0);
  HAL_NVIC_EnableIRQ(DMA1_Stream5_IRQn);
  /* DMA1_Stream6_IRQn interrupt configuration */
  HAL_NVIC_SetPriority(DMA1_Stream6_IRQn, 0, 0);
  HAL_NVIC_EnableIRQ(DMA1_Stream6_IRQn);
  /* DMA2_Stream6_IRQn interrupt configuration */
  HAL_NVIC_SetPriority(DMA2_Stream6_IRQn, 0, 0);
  HAL_NVIC_EnableIRQ(DMA2_Stream6_IRQn);

}

static void MX_GPIO_Init(void)
{
  GPIO_InitTypeDef GPIO_InitStruct = {0};

  /* GPIO Ports Clock Enable */
  __HAL_RCC_GPIOE_CLK_ENABLE();
  __HAL_RCC_GPIOI_CLK_ENABLE();
  __HAL_RCC_GPIOC_CLK_ENABLE();
  __HAL_RCC_GPIOF_CLK_ENABLE();
  __HAL_RCC_GPIOA_CLK_ENABLE();
  __HAL_RCC_GPIOH_CLK_ENABLE();
  __HAL_RCC_GPIOB_CLK_ENABLE();
  __HAL_RCC_GPIOG_CLK_ENABLE();
  __HAL_RCC_GPIOD_CLK_ENABLE();

  /*Configure GPIO pin Output Level */
  HAL_GPIO_WritePin(GPIOE, O_OptIn4_Pin|O_OptIn3_Pin|O_OptIn2_Pin|O_OptIn1_Pin
                          |O_OptSel_Pin|O_OptMode_Pin, GPIO_PIN_RESET);

  /*Configure GPIO pin Output Level */
  HAL_GPIO_WritePin(GPIOI, O_BlueLed_R_Pin|O_USART6_TR_Pin, GPIO_PIN_RESET);

  /*Configure GPIO pin Output Level */
  HAL_GPIO_WritePin(GPIOF, O_Wheel1Reset_Pin|O_WheelDCLock_Pin|O_Wheel2CW_Pin|O_Wheel2CCW_Pin
                          |O_Wheel2Reset_Pin|O_Wheel1Load_Pin|O_BlueLed_L_Pin|O_RedLed_L_Pin
                          |O_GreenLed_L_Pin|O_Lift1AlarmReset_Pin|O_LiftStopMode_Pin, GPIO_PIN_RESET);

  /*Configure GPIO pin Output Level */
  HAL_GPIO_WritePin(GPIOH, O_AlarmCh1_Pin|O_Wheel_STO_Pin|O_AlarmCh3_Pin|O_AlarmCh4_Pin
                          |O_Lidar1In4_Pin|O_Lidar1In5_Pin|O_Lidar1In3_Pin|O_Lidar1In2_Pin, GPIO_PIN_RESET);

  /*Configure GPIO pin Output Level */
  HAL_GPIO_WritePin(GPIOC, O_TurnStopMode_Pin|O_GreenLed_R_Pin|O_RedLed_R_Pin, GPIO_PIN_RESET);

  /*Configure GPIO pin Output Level */
  HAL_GPIO_WritePin(GPIOB, O_TableLed_Pin|O_LiftBrake_Pin|O_Lift2AlarmReset_Pin, GPIO_PIN_RESET);

  /*Configure GPIO pin Output Level */
  HAL_GPIO_WritePin(GPIOG, O_Lift1CCW_Pin|O_Lift1CW_Pin|O_BrakeRelay_Pin|O_LiftRelay_Pin
                          |O_TurnRelay_Pin|O_DriveRelay_Pin|O_ChargeRelay_Pin, GPIO_PIN_RESET);

  /*Configure GPIO pin Output Level */
  HAL_GPIO_WritePin(O_AddRelay_GPIO_Port, O_AddRelay_Pin, GPIO_PIN_SET);

  /*Configure GPIO pin Output Level */
  HAL_GPIO_WritePin(GPIOD, O_TurnAlarmReset_Pin|O_TurnBrake_Pin|O_TurnCCW_Pin|O_TurnCW_Pin
                          |O_Lidar1In1_Pin|O_Lidar2In5_Pin|O_Lidar2In4_Pin|O_Lidar2In3_Pin
                          |O_Lidar2In2_Pin|O_Lidar2In1_Pin, GPIO_PIN_RESET);

  /*Configure GPIO pin Output Level */
  HAL_GPIO_WritePin(GPIOA, O_Wheel1CCW_Pin|O_Wheel1CW_Pin|O_Lift2CCW_Pin|O_Lift2CW_Pin
                          |O_Wheel2Load_Pin, GPIO_PIN_RESET);

  /*Configure GPIO pins : O_OptIn4_Pin O_OptIn3_Pin O_OptIn2_Pin O_OptIn1_Pin
                           O_OptSel_Pin O_OptMode_Pin */
  GPIO_InitStruct.Pin = O_OptIn4_Pin|O_OptIn3_Pin|O_OptIn2_Pin|O_OptIn1_Pin
                          |O_OptSel_Pin|O_OptMode_Pin;
  GPIO_InitStruct.Mode = GPIO_MODE_OUTPUT_PP;
  GPIO_InitStruct.Pull = GPIO_NOPULL;
  GPIO_InitStruct.Speed = GPIO_SPEED_FREQ_LOW;
  HAL_GPIO_Init(GPIOE, &GPIO_InitStruct);

  /*Configure GPIO pins : O_BlueLed_R_Pin O_USART6_TR_Pin */
  GPIO_InitStruct.Pin = O_BlueLed_R_Pin|O_USART6_TR_Pin;
  GPIO_InitStruct.Mode = GPIO_MODE_OUTPUT_PP;
  GPIO_InitStruct.Pull = GPIO_NOPULL;
  GPIO_InitStruct.Speed = GPIO_SPEED_FREQ_LOW;
  HAL_GPIO_Init(GPIOI, &GPIO_InitStruct);

  /*Configure GPIO pins : INT_Wheel1Pulse_Pin INT_Wheel2Pulse_Pin */
  GPIO_InitStruct.Pin = INT_Wheel1Pulse_Pin|INT_Wheel2Pulse_Pin;
  GPIO_InitStruct.Mode = GPIO_MODE_IT_RISING;
  GPIO_InitStruct.Pull = GPIO_NOPULL;
  HAL_GPIO_Init(GPIOC, &GPIO_InitStruct);

  /*Configure GPIO pins : I_Wheel1Dir_Pin I_BrakeReleSw_F_Pin I_ResetSw_F_Pin I_Bumber2_Pin
                           I_Lift2Alm_Pin I_TurnEncoderBch_Pin */
  GPIO_InitStruct.Pin = I_Wheel1Dir_Pin|I_BrakeReleSw_F_Pin|I_ResetSw_F_Pin|I_Bumber2_Pin
                          |I_Lift2Alm_Pin|I_TurnEncoderBch_Pin;
  GPIO_InitStruct.Mode = GPIO_MODE_INPUT;
  GPIO_InitStruct.Pull = GPIO_NOPULL;
  HAL_GPIO_Init(GPIOC, &GPIO_InitStruct);

  /*Configure GPIO pins : O_Wheel1Reset_Pin O_WheelDCLock_Pin O_Wheel2CW_Pin O_Wheel2CCW_Pin
                           O_Wheel2Reset_Pin O_Wheel1Load_Pin O_BlueLed_L_Pin O_RedLed_L_Pin
                           O_GreenLed_L_Pin */
  GPIO_InitStruct.Pin = O_Wheel1Reset_Pin|O_WheelDCLock_Pin|O_Wheel2CW_Pin|O_Wheel2CCW_Pin
                          |O_Wheel2Reset_Pin|O_Wheel1Load_Pin|O_BlueLed_L_Pin|O_RedLed_L_Pin
                          |O_GreenLed_L_Pin;
  GPIO_InitStruct.Mode = GPIO_MODE_OUTPUT_PP;
  GPIO_InitStruct.Pull = GPIO_NOPULL;
  GPIO_InitStruct.Speed = GPIO_SPEED_FREQ_LOW;
  HAL_GPIO_Init(GPIOF, &GPIO_InitStruct);

  /*Configure GPIO pins : I_TurnBrakeSw_F_Pin I_Wheel1Error_Pin I_Wheel2Dir_Pin */
  GPIO_InitStruct.Pin = I_TurnBrakeSw_F_Pin|I_Wheel1Error_Pin|I_Wheel2Dir_Pin;
  GPIO_InitStruct.Mode = GPIO_MODE_INPUT;
  GPIO_InitStruct.Pull = GPIO_NOPULL;
  HAL_GPIO_Init(GPIOF, &GPIO_InitStruct);

  /*Configure GPIO pins : I_LiftSw_F_Pin I_TurnBrakeSw_R_Pin I_Bumper1_Pin */
  GPIO_InitStruct.Pin = I_LiftSw_F_Pin|I_TurnBrakeSw_R_Pin|I_Bumper1_Pin;
  GPIO_InitStruct.Mode = GPIO_MODE_INPUT;
  GPIO_InitStruct.Pull = GPIO_NOPULL;
  HAL_GPIO_Init(GPIOA, &GPIO_InitStruct);

  /*Configure GPIO pins : O_AlarmCh1_Pin O_Wheel_STO_Pin O_AlarmCh3_Pin O_AlarmCh4_Pin
                           O_AddRelay_Pin O_Lidar1In4_Pin O_Lidar1In5_Pin O_Lidar1In3_Pin
                           O_Lidar1In2_Pin */
  GPIO_InitStruct.Pin = O_AlarmCh1_Pin|O_Wheel_STO_Pin|O_AlarmCh3_Pin|O_AlarmCh4_Pin
                          |O_AddRelay_Pin|O_Lidar1In4_Pin|O_Lidar1In5_Pin|O_Lidar1In3_Pin
                          |O_Lidar1In2_Pin;
  GPIO_InitStruct.Mode = GPIO_MODE_OUTPUT_PP;
  GPIO_InitStruct.Pull = GPIO_NOPULL;
  GPIO_InitStruct.Speed = GPIO_SPEED_FREQ_LOW;
  HAL_GPIO_Init(GPIOH, &GPIO_InitStruct);

  /*Configure GPIO pin : O_TurnStopMode_Pin */
  GPIO_InitStruct.Pin = O_TurnStopMode_Pin;
  GPIO_InitStruct.Mode = GPIO_MODE_OUTPUT_PP;
  GPIO_InitStruct.Pull = GPIO_PULLUP;
  GPIO_InitStruct.Speed = GPIO_SPEED_FREQ_LOW;
  HAL_GPIO_Init(O_TurnStopMode_GPIO_Port, &GPIO_InitStruct);

  /*Configure GPIO pin : O_TableLed_Pin */
  GPIO_InitStruct.Pin = O_TableLed_Pin;
  GPIO_InitStruct.Mode = GPIO_MODE_OUTPUT_PP;
  GPIO_InitStruct.Pull = GPIO_NOPULL;
  GPIO_InitStruct.Speed = GPIO_SPEED_FREQ_LOW;
  HAL_GPIO_Init(O_TableLed_GPIO_Port, &GPIO_InitStruct);

  /*Configure GPIO pins : O_LiftBrake_Pin O_Lift2AlarmReset_Pin */
  GPIO_InitStruct.Pin = O_LiftBrake_Pin|O_Lift2AlarmReset_Pin;
  GPIO_InitStruct.Mode = GPIO_MODE_OUTPUT_PP;
  GPIO_InitStruct.Pull = GPIO_PULLUP;
  GPIO_InitStruct.Speed = GPIO_SPEED_FREQ_LOW;
  HAL_GPIO_Init(GPIOB, &GPIO_InitStruct);

  /*Configure GPIO pins : O_Lift1AlarmReset_Pin O_LiftStopMode_Pin */
  GPIO_InitStruct.Pin = O_Lift1AlarmReset_Pin|O_LiftStopMode_Pin;
  GPIO_InitStruct.Mode = GPIO_MODE_OUTPUT_PP;
  GPIO_InitStruct.Pull = GPIO_PULLUP;
  GPIO_InitStruct.Speed = GPIO_SPEED_FREQ_LOW;
  HAL_GPIO_Init(GPIOF, &GPIO_InitStruct);

  /*Configure GPIO pins : O_Lift1CCW_Pin O_Lift1CW_Pin */
  GPIO_InitStruct.Pin = O_Lift1CCW_Pin|O_Lift1CW_Pin;
  GPIO_InitStruct.Mode = GPIO_MODE_OUTPUT_PP;
  GPIO_InitStruct.Pull = GPIO_PULLUP;
  GPIO_InitStruct.Speed = GPIO_SPEED_FREQ_LOW;
  HAL_GPIO_Init(GPIOG, &GPIO_InitStruct);

  /*Configure GPIO pin : I_BrakeReleSw_R_Pin */
  GPIO_InitStruct.Pin = I_BrakeReleSw_R_Pin;
  GPIO_InitStruct.Mode = GPIO_MODE_INPUT;
  GPIO_InitStruct.Pull = GPIO_NOPULL;
  HAL_GPIO_Init(I_BrakeReleSw_R_GPIO_Port, &GPIO_InitStruct);

  /*Configure GPIO pins : I_Turn0degSens_Pin I_Turn90degSens_Pin I_Turn180degSens_Pin I_Turn270degSens_Pin
                           I_Lift2UpLimitSens_Pin I_Lift2UpSens_Pin I_Lift2DownSens_Pin I_Lift2DownLimitSens_Pin */
  GPIO_InitStruct.Pin = I_Turn0degSens_Pin|I_Turn90degSens_Pin|I_Turn180degSens_Pin|I_Turn270degSens_Pin
                          |I_Lift2UpLimitSens_Pin|I_Lift2UpSens_Pin|I_Lift2DownSens_Pin|I_Lift2DownLimitSens_Pin;
  GPIO_InitStruct.Mode = GPIO_MODE_INPUT;
  GPIO_InitStruct.Pull = GPIO_PULLUP;
  HAL_GPIO_Init(GPIOE, &GPIO_InitStruct);

  /*Configure GPIO pins : I_Lift1UpLimitSens_Pin I_Lift1UpSens_Pin I_Lift1DownSens_Pin I_Lift1DownLimitSens_Pin */
  GPIO_InitStruct.Pin = I_Lift1UpLimitSens_Pin|I_Lift1UpSens_Pin|I_Lift1DownSens_Pin|I_Lift1DownLimitSens_Pin;
  GPIO_InitStruct.Mode = GPIO_MODE_INPUT;
  GPIO_InitStruct.Pull = GPIO_PULLUP;
  HAL_GPIO_Init(GPIOH, &GPIO_InitStruct);

  /*Configure GPIO pins : I_Lift1Alm_Pin I_EmergencyMoni_Pin I_LiftSw_R_Pin I_ResetSw_R_Pin
                           I_OptGo_Pin I_OptOut4_Pin I_OptOut3_Pin I_OptOut2_Pin
                           I_OptOut1_Pin */
  GPIO_InitStruct.Pin = I_Lift1Alm_Pin|I_EmergencyMoni_Pin|I_LiftSw_R_Pin|I_ResetSw_R_Pin
                          |I_OptGo_Pin|I_OptOut4_Pin|I_OptOut3_Pin|I_OptOut2_Pin
                          |I_OptOut1_Pin;
  GPIO_InitStruct.Mode = GPIO_MODE_INPUT;
  GPIO_InitStruct.Pull = GPIO_NOPULL;
  HAL_GPIO_Init(GPIOB, &GPIO_InitStruct);

  /*Configure GPIO pin : INT_TurnEncorder_Pin */
  GPIO_InitStruct.Pin = INT_TurnEncorder_Pin;
  GPIO_InitStruct.Mode = GPIO_MODE_IT_RISING;
  GPIO_InitStruct.Pull = GPIO_NOPULL;
  HAL_GPIO_Init(INT_TurnEncorder_GPIO_Port, &GPIO_InitStruct);

  /*Configure GPIO pins : I_Wheel2Error_Pin I_TurnAlm_Pin */
  GPIO_InitStruct.Pin = I_Wheel2Error_Pin|I_TurnAlm_Pin;
  GPIO_InitStruct.Mode = GPIO_MODE_INPUT;
  GPIO_InitStruct.Pull = GPIO_NOPULL;
  HAL_GPIO_Init(GPIOD, &GPIO_InitStruct);

  /*Configure GPIO pins : O_TurnAlarmReset_Pin O_TurnBrake_Pin O_TurnCCW_Pin O_TurnCW_Pin */
  GPIO_InitStruct.Pin = O_TurnAlarmReset_Pin|O_TurnBrake_Pin|O_TurnCCW_Pin|O_TurnCW_Pin;
  GPIO_InitStruct.Mode = GPIO_MODE_OUTPUT_PP;
  GPIO_InitStruct.Pull = GPIO_PULLUP;
  GPIO_InitStruct.Speed = GPIO_SPEED_FREQ_LOW;
  HAL_GPIO_Init(GPIOD, &GPIO_InitStruct);

  /*Configure GPIO pins : O_BrakeRelay_Pin O_LiftRelay_Pin O_TurnRelay_Pin O_DriveRelay_Pin
                           O_ChargeRelay_Pin */
  GPIO_InitStruct.Pin = O_BrakeRelay_Pin|O_LiftRelay_Pin|O_TurnRelay_Pin|O_DriveRelay_Pin
                          |O_ChargeRelay_Pin;
  GPIO_InitStruct.Mode = GPIO_MODE_OUTPUT_PP;
  GPIO_InitStruct.Pull = GPIO_NOPULL;
  GPIO_InitStruct.Speed = GPIO_SPEED_FREQ_LOW;
  HAL_GPIO_Init(GPIOG, &GPIO_InitStruct);

  /*Configure GPIO pins : I_Lift1Tim_Pin I_Lift2Tim_Pin */
  GPIO_InitStruct.Pin = I_Lift1Tim_Pin|I_Lift2Tim_Pin;
  GPIO_InitStruct.Mode = GPIO_MODE_IT_RISING;
  GPIO_InitStruct.Pull = GPIO_NOPULL;
  HAL_GPIO_Init(GPIOG, &GPIO_InitStruct);

  /*Configure GPIO pins : O_GreenLed_R_Pin O_RedLed_R_Pin */
  GPIO_InitStruct.Pin = O_GreenLed_R_Pin|O_RedLed_R_Pin;
  GPIO_InitStruct.Mode = GPIO_MODE_OUTPUT_PP;
  GPIO_InitStruct.Pull = GPIO_NOPULL;
  GPIO_InitStruct.Speed = GPIO_SPEED_FREQ_LOW;
  HAL_GPIO_Init(GPIOC, &GPIO_InitStruct);

  /*Configure GPIO pins : O_Wheel1CCW_Pin O_Wheel1CW_Pin O_Wheel2Load_Pin */
  GPIO_InitStruct.Pin = O_Wheel1CCW_Pin|O_Wheel1CW_Pin|O_Wheel2Load_Pin;
  GPIO_InitStruct.Mode = GPIO_MODE_OUTPUT_PP;
  GPIO_InitStruct.Pull = GPIO_NOPULL;
  GPIO_InitStruct.Speed = GPIO_SPEED_FREQ_LOW;
  HAL_GPIO_Init(GPIOA, &GPIO_InitStruct);

  /*Configure GPIO pins : O_Lift2CCW_Pin O_Lift2CW_Pin */
  GPIO_InitStruct.Pin = O_Lift2CCW_Pin|O_Lift2CW_Pin;
  GPIO_InitStruct.Mode = GPIO_MODE_OUTPUT_PP;
  GPIO_InitStruct.Pull = GPIO_PULLUP;
  GPIO_InitStruct.Speed = GPIO_SPEED_FREQ_LOW;
  HAL_GPIO_Init(GPIOA, &GPIO_InitStruct);

  /*Configure GPIO pin : I_Lidar1Trouble_Pin */
  GPIO_InitStruct.Pin = I_Lidar1Trouble_Pin;
  GPIO_InitStruct.Mode = GPIO_MODE_INPUT;
  GPIO_InitStruct.Pull = GPIO_NOPULL;
  HAL_GPIO_Init(I_Lidar1Trouble_GPIO_Port, &GPIO_InitStruct);

  /*Configure GPIO pins : I_Lidar1Out3_Pin I_Lidar2Out2_Pin */
  GPIO_InitStruct.Pin = I_Lidar1Out3_Pin|I_Lidar2Out2_Pin;
  GPIO_InitStruct.Mode = GPIO_MODE_INPUT;
  GPIO_InitStruct.Pull = GPIO_NOPULL;
  HAL_GPIO_Init(GPIOI, &GPIO_InitStruct);

  /*Configure GPIO pins : O_Lidar1In1_Pin O_Lidar2In5_Pin O_Lidar2In4_Pin O_Lidar2In3_Pin
                           O_Lidar2In2_Pin O_Lidar2In1_Pin */
  GPIO_InitStruct.Pin = O_Lidar1In1_Pin|O_Lidar2In5_Pin|O_Lidar2In4_Pin|O_Lidar2In3_Pin
                          |O_Lidar2In2_Pin|O_Lidar2In1_Pin;
  GPIO_InitStruct.Mode = GPIO_MODE_OUTPUT_PP;
  GPIO_InitStruct.Pull = GPIO_NOPULL;
  GPIO_InitStruct.Speed = GPIO_SPEED_FREQ_LOW;
  HAL_GPIO_Init(GPIOD, &GPIO_InitStruct);

  /*Configure GPIO pins : I_Lidar1Out2_Pin I_Lidar1Out1_Pin I_Lidar2Trouble_Pin I_Lidar2Out3_Pin
                           I_Lidar2Out1_Pin */
  GPIO_InitStruct.Pin = I_Lidar1Out2_Pin|I_Lidar1Out1_Pin|I_Lidar2Trouble_Pin|I_Lidar2Out3_Pin
                          |I_Lidar2Out1_Pin;
  GPIO_InitStruct.Mode = GPIO_MODE_INPUT;
  GPIO_InitStruct.Pull = GPIO_NOPULL;
  HAL_GPIO_Init(GPIOG, &GPIO_InitStruct);

  /* EXTI interrupt init*/
  HAL_NVIC_SetPriority(EXTI9_5_IRQn, 0, 0);
  HAL_NVIC_EnableIRQ(EXTI9_5_IRQn);

  HAL_NVIC_SetPriority(EXTI15_10_IRQn, 0, 0);
  HAL_NVIC_EnableIRQ(EXTI15_10_IRQn);

}

/* USER CODE BEGIN 4 */
void enc_pulse_tim_start(void){
	// TIM6 start (Wheel1 エンコーダパルス間隔計測用)
	TIM6 ->CR1 |= TIM_CR1_UDIS;
	TIM6 ->DIER &= ~TIM_DIER_UDE;
	TIM6 ->DIER &= ~TIM_DIER_UIE;
	TIM6 ->CR1 |= TIM_CR1_CEN;
	// TIM7 start (Wheel2 エンコーダパルス間隔計測用)
	TIM7 ->CR1 |= TIM_CR1_UDIS;
	TIM7 ->DIER &= ~TIM_DIER_UDE;
	TIM7 ->DIER &= ~TIM_DIER_UIE;
	TIM7 ->CR1 |= TIM_CR1_CEN;
	// TIM5 start (ターンテーブル エンコーダパルス間隔計測用)
	TIM5 ->CR1 |= TIM_CR1_UDIS;
	TIM5 ->DIER &= ~TIM_DIER_UDE;
	TIM5 ->DIER &= ~TIM_DIER_UIE;
	TIM5 ->CR1 |= TIM_CR1_CEN;
}

void enc_pulse_tim_cnt_reset(void){
	// タイマのオーバーフロー時に処理速度低下するためオーバーフローを回避する
	if ((TIM6 -> CNT) > 40000){
		TIM6 -> CNT = 0;	// wheel1エンコーダパルス周期計測用(シンクロターン用)
	}
	if ((TIM7 -> CNT) > 40000){
		TIM7 -> CNT = 0;	// wheel2エンコーダパルス周期計測用(シンクロターン用)
	}
	if ((TIM5 -> CNT) > 2500000000){
		TIM5 -> CNT = 0;	// ターンテーブルエンコーダパルス周期計測用(シンクロターン用)
	}
}

void HAL_GPIO_EXTI_Callback(uint16_t GPIO_Pin) {
    // direction & pulse count
#if WHEEL_ENC_FILTER == FILTER_DISABLE
	if (GPIO_Pin == INT_Wheel1Pulse_Pin) {		// Wheel1 encoder PC13
		// パルスの更新周期を計測
		tim6_cnt = TIM6 -> CNT;
		TIM6 -> CNT = 0;
	    if (HAL_GPIO_ReadPin(I_Wheel1Dir_GPIO_Port, I_Wheel1Dir_Pin) == GPIO_PIN_SET) {
			r_wheel_enc++;
	    } else {
			r_wheel_enc--;
	    }
	} else if (GPIO_Pin == INT_Wheel2Pulse_Pin) {	// Wheel2 encoder PC15
		// パルスの更新周期を計測
		tim7_cnt = TIM7 -> CNT;
		TIM7 -> CNT = 0;
		if (HAL_GPIO_ReadPin(I_Wheel2Dir_GPIO_Port, I_Wheel2Dir_Pin) == GPIO_PIN_SET) {
			l_wheel_enc--;
		} else {
			l_wheel_enc++;
		}
#else
	if ((GPIO_Pin == INT_Wheel1Pulse_Pin) && ((TIM6 -> CNT) > 20)) {		// Wheel1 encoder PC13
		// ノイズ対策： 2.1kHz(1.7m/s相当)以上のパルスはカウントしない
		tim6_cnt = TIM6 -> CNT;
		TIM6 -> CNT = 0;
	    if (HAL_GPIO_ReadPin(I_Wheel1Dir_GPIO_Port, I_Wheel1Dir_Pin) == GPIO_PIN_SET) {
			r_wheel_enc++;
	    } else {
			r_wheel_enc--;
	    }
	} else if (GPIO_Pin == INT_Wheel2Pulse_Pin && ((TIM7 -> CNT) > 20)) {	// Wheel2 encoder PC15
		// ノイズ対策： 2.1kHz(1.7m/s相当)以上のパルスはカウントしない
		tim7_cnt = TIM7 -> CNT;
		TIM7 -> CNT = 0;
		if (HAL_GPIO_ReadPin(I_Wheel2Dir_GPIO_Port, I_Wheel2Dir_Pin) == GPIO_PIN_SET) {
			l_wheel_enc--;
		} else {
			l_wheel_enc++;
		}
#endif
	} else if (GPIO_Pin == I_Lift1Tim_Pin) {	// PG7 Lift1 encoder
		add_lift1_enc();
	} else if (GPIO_Pin == I_Lift2Tim_Pin) {	// PG8 Lift2 encoder
		add_lift2_enc();
	} else if (GPIO_Pin == INT_TurnEncorder_Pin) {	//PD9 Turn encoder
		// パルスの更新周期を計測
		tim5_cnt = TIM5 -> CNT;
		TIM5 -> CNT = 0;
		if (HAL_GPIO_ReadPin(I_TurnEncoderBch_GPIO_Port, I_TurnEncoderBch_Pin) == GPIO_PIN_RESET){			// phase B fall down
			turn_encoder--;
		} else {
			turn_encoder++;
		}
	}
}

uint16_t get_l_wheel_enc_cnt(void) {
	return tim7_cnt;
}

uint16_t get_r_wheel_enc_cnt(void) {
	return tim6_cnt;
}

uint16_t get_turn_encoder(void) {
	return turn_encoder;
}

uint32_t get_turn_enc_cnt(void) {
	return tim5_cnt;
}

void int_1msCallback(void){
    // ----timer count up-----
	time_run();

	tbt();
}

/* USER CODE END 4 */

void Error_Handler(void)
{
}

/************************ (C) COPYRIGHT STMicroelectronics *****END OF FILE****/
